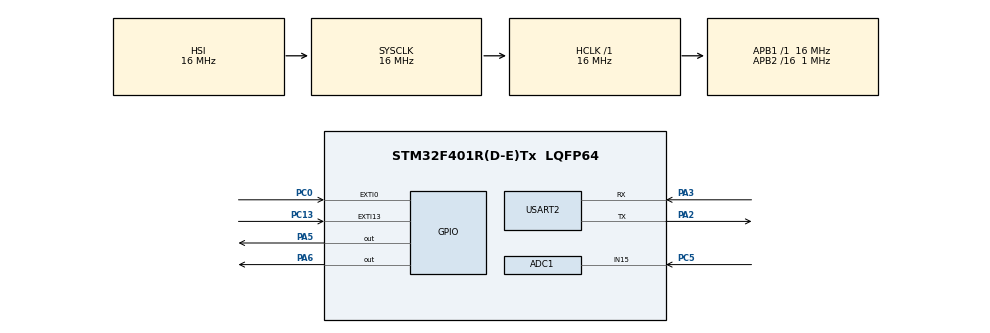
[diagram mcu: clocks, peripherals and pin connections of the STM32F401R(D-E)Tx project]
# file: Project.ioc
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ADC1.Channel-4\#ChannelRegularConversion=ADC_CHANNEL_15
ADC1.NbrOfConversionFlag=1
ADC1.Rank-4\#ChannelRegularConversion=1
ADC1.SamplingTime-4\#ChannelRegularConversion=ADC_SAMPLETIME_3CYCLES
ADC1.master=1
Dma.Request0=USART2_RX
Dma.Request1=USART2_TX
Dma.USART2_RX.0.Direction=DMA_PERIPH_TO_MEMORY
Dma.USART2_RX.0.FIFOMode=DMA_FIFOMODE_DISABLE
Dma.USART2_RX.0.Instance=DMA1_Stream5
Dma.USART2_RX.0.MemDataAlignment=DMA_MDATAALIGN_BYTE
Dma.USART2_RX.0.MemInc=DMA_MINC_ENABLE
Dma.USART2_RX.0.Mode=DMA_NORMAL
Dma.USART2_RX.0.PeriphDataAlignment=DMA_PDATAALIGN_BYTE
Dma.USART2_RX.0.PeriphInc=DMA_PINC_DISABLE
Dma.USART2_RX.0.Priority=DMA_PRIORITY_LOW
Dma.USART2_TX.1.Direction=DMA_MEMORY_TO_PERIPH
Dma.USART2_TX.1.FIFOMode=DMA_FIFOMODE_DISABLE
Dma.USART2_TX.1.Instance=DMA1_Stream6
Dma.USART2_TX.1.MemDataAlignment=DMA_MDATAALIGN_BYTE
Dma.USART2_TX.1.MemInc=DMA_MINC_ENABLE
Dma.USART2_TX.1.Mode=DMA_NORMAL
Dma.USART2_TX.1.PeriphDataAlignment=DMA_PDATAALIGN_BYTE
Dma.USART2_TX.1.PeriphInc=DMA_PINC_DISABLE
Dma.USART2_TX.1.Priority=DMA_PRIORITY_LOW
MBEDTLS.MBEDTLS_CIPHER_MODE_CBC=1
MBEDTLS.MBEDTLS_PKCS5_C=1
Mcu.Family=STM32F4
Mcu.Name=STM32F401R(D-E)Tx
Mcu.Package=LQFP64
NVIC.DMA1_Stream5_IRQn=true\:0\:0\:false\:false\:true\:false\:true\:true
NVIC.DMA1_Stream6_IRQn=true\:0\:0\:false\:false\:true\:false\:true\:true
NVIC.EXTI0_IRQn=true\:0\:0\:false\:false\:true\:true\:true\:true
NVIC.EXTI15_10_IRQn=true\:0\:0\:false\:false\:true\:true\:true\:true
NVIC.PriorityGroup=NVIC_PRIORITYGROUP_4
NVIC.TIM1_UP_TIM10_IRQn=true\:0\:0\:false\:false\:true\:true\:true\:true
NVIC.USART2_IRQn=true\:0\:0\:false\:false\:true\:true\:true\:true
PA2.Mode=Asynchronous
PA2.Signal=USART2_TX
PA3.Mode=Asynchronous
PA3.Signal=USART2_RX
PA5.Signal=GPIO_Output
PA6.Signal=GPIO_Output
PC0.GPIO_ModeDefaultEXTI=GPIO_MODE_IT_FALLING
PC0.GPIO_PuPd=GPIO_PULLUP
PC0.Signal=GPXTI0
PC13-ANTI_TAMP.Signal=GPXTI13
PC5.Signal=ADCx_IN15
ProjectManager.HeapSize=0x200
ProjectManager.StackSize=0x400
ProjectManager.TargetToolchain=Makefile
RCC.AHBFreq_Value=16000000
RCC.APB1Freq_Value=16000000
RCC.APB1TimFreq_Value=16000000
RCC.APB2CLKDivider=RCC_HCLK_DIV16
RCC.APB2Freq_Value=1000000
RCC.APB2TimFreq_Value=2000000
RCC.CortexFreq_Value=16000000
RCC.HCLKFreq_Value=16000000
RCC.HSE_VALUE=25000000
RCC.HSI_VALUE=16000000
RCC.LSE_VALUE=32768
RCC.SYSCLKFreq_VALUE=16000000
RCC.VCOOutputFreq_Value=192000000
SH.ADCx_IN15.0=ADC1_IN15,IN15
TIM10.Period=250 - 1
TIM10.Prescaler=2000 - 1
USART2.VirtualMode=VM_ASYNC
VP_MBEDTLS_VS_MBEDTLS.Mode=Enabled
VP_TIM10_VS_ClockSourceINT.Mode=Enable_Timer
board=custom

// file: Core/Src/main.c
/* USER CODE BEGIN Header */
/**
  ******************************************************************************
  * @file           : main.c
  * @brief          : Main program body
  ******************************************************************************
  * @attention
  *
  * Copyright (c) 2023 STMicroelectronics.
  * All rights reserved.
  *
  * This software is licensed under terms that can be found in the LICENSE file
  * in the root directory of this software component.
  * If no LICENSE file comes with this software, it is provided AS-IS.
  *
  ******************************************************************************
  */
/* USER CODE END Header */
#include "main.h"
#include "mbedtls.h"

/* USER CODE BEGIN Includes */
#include <stdio.h>
#include "logic.h"
#include "stm32f4xx_hal.h"

/* USER CODE END Includes */

ADC_HandleTypeDef hadc1;

TIM_HandleTypeDef htim10;

UART_HandleTypeDef huart2;
DMA_HandleTypeDef hdma_usart2_rx;
DMA_HandleTypeDef hdma_usart2_tx;

/* USER CODE BEGIN PV */

Key key = {
    .generated = 0,
    .value = { 0 },
};

/* USER CODE END PV */

void SystemClock_Config(void);
static void MX_GPIO_Init(void);
static void MX_DMA_Init(void);
static void MX_TIM10_Init(void);
static void MX_USART2_UART_Init(void);
static void MX_ADC1_Init(void);

int main(void)
{

  /* MCU Configuration--------------------------------------------------------*/

  /* Reset of all peripherals, Initializes the Flash interface and the Systick. */
  HAL_Init();

  /* Configure the system clock */
  SystemClock_Config();

  /* Initialize all configured peripherals */
  MX_GPIO_Init();
  MX_DMA_Init();
  MX_TIM10_Init();
  MX_USART2_UART_Init();
  MX_MBEDTLS_Init();
  MX_ADC1_Init();
  /* USER CODE BEGIN 2 */
  HAL_TIM_Base_Start_IT(&htim10);

  /* USER CODE END 2 */

  /* Infinite loop */
  /* USER CODE BEGIN WHILE */
  HAL_UART_Receive_IT(&huart2, (uint8_t *)&header, 2);
  // printf("hello it's %lu at %x\r\n", key, (uint32_t)&key);
  while (1)
  {
    /* USER CODE END WHILE */

  }
}

void SystemClock_Config(void)
{
  RCC_OscInitTypeDef RCC_OscInitStruct = {0};
  RCC_ClkInitTypeDef RCC_ClkInitStruct = {0};

  /** Configure the main internal regulator output voltage
  */
  __HAL_RCC_PWR_CLK_ENABLE();
  __HAL_PWR_VOLTAGESCALING_CONFIG(PWR_REGULATOR_VOLTAGE_SCALE2);

  /** Initializes the RCC Oscillators according to the specified parameters
  * in the RCC_OscInitTypeDef structure.
  */
  RCC_OscInitStruct.OscillatorType = RCC_OSCILLATORTYPE_HSI;
  RCC_OscInitStruct.HSIState = RCC_HSI_ON;
  RCC_OscInitStruct.HSICalibrationValue = RCC_HSICALIBRATION_DEFAULT;
  RCC_OscInitStruct.PLL.PLLState = RCC_PLL_NONE;
  if (HAL_RCC_OscConfig(&RCC_OscInitStruct) != HAL_OK)
  {
    Error_Handler();
  }

  /** Initializes the CPU, AHB and APB buses clocks
  */
  RCC_ClkInitStruct.ClockType = RCC_CLOCKTYPE_HCLK|RCC_CLOCKTYPE_SYSCLK
                              |RCC_CLOCKTYPE_PCLK1|RCC_CLOCKTYPE_PCLK2;
  RCC_ClkInitStruct.SYSCLKSource = RCC_SYSCLKSOURCE_HSI;
  RCC_ClkInitStruct.AHBCLKDivider = RCC_SYSCLK_DIV1;
  RCC_ClkInitStruct.APB1CLKDivider = RCC_HCLK_DIV1;
  RCC_ClkInitStruct.APB2CLKDivider = RCC_HCLK_DIV16;

  if (HAL_RCC_ClockConfig(&RCC_ClkInitStruct, FLASH_LATENCY_0) != HAL_OK)
  {
    Error_Handler();
  }
}

static void MX_ADC1_Init(void)
{

  ADC_ChannelConfTypeDef sConfig = {0};

   //!!! HAL_ADC_Init is commented because some parameters are missing
  //hadc.Instance = ADC1;
  //hadc.Init.ClockPrescaler = ;
  //hadc.Init.Resolution = ADC_RESOLUTION_12B;
  //hadc.Init.ScanConvMode = DISABLE;
  //hadc.Init.ContinuousConvMode = DISABLE;
  //hadc.Init.DiscontinuousConvMode = DISABLE;
  //hadc.Init.ExternalTrigConvEdge = ADC_EXTERNALTRIGCONVEDGE_NONE;
  //hadc.Init.ExternalTrigConv = ADC_SOFTWARE_START;
  //hadc.Init.DataAlign = ADC_DATAALIGN_RIGHT;
  //hadc.Init.NbrOfConversion = 1;
  //hadc.Init.DMAContinuousRequests = DISABLE;
  //hadc.Init.EOCSelection = ADC_EOC_SINGLE_CONV;
    //HAL_ADC_Init(&hadc);

   //!!! HAL_ADC_ConfigChannel is commented because some parameters are missing
  //sConfig.Channel = ADC_CHANNEL_15;
  //sConfig.Rank = 1;
  //sConfig.SamplingTime = ADC_SAMPLETIME_3CYCLES;
    //HAL_ADC_ConfigChannel(&hadc, &sConfig);

}

static void MX_TIM10_Init(void)
{

  htim10.Instance = TIM10;
  htim10.Init.Prescaler = 2000 - 1;
  htim10.Init.CounterMode = TIM_COUNTERMODE_UP;
  htim10.Init.Period = 250 - 1;
  htim10.Init.ClockDivision = TIM_CLOCKDIVISION_DIV1;
  htim10.Init.AutoReloadPreload = TIM_AUTORELOAD_PRELOAD_DISABLE;
  if (HAL_TIM_Base_Init(&htim10) != HAL_OK)
  {
    Error_Handler();
  }

}

static void MX_USART2_UART_Init(void)
{

  huart2.Instance = USART2;
  huart2.Init.BaudRate = 115200;
  huart2.Init.WordLength = UART_WORDLENGTH_8B;
  huart2.Init.StopBits = UART_STOPBITS_1;
  huart2.Init.Parity = UART_PARITY_NONE;
  huart2.Init.Mode = UART_MODE_TX_RX;
  huart2.Init.HwFlowCtl = UART_HWCONTROL_NONE;
  huart2.Init.OverSampling = UART_OVERSAMPLING_16;
  if (HAL_UART_Init(&huart2) != HAL_OK)
  {
    Error_Handler();
  }

}

static void MX_DMA_Init(void)
{

  /* DMA controller clock enable */
  __HAL_RCC_DMA1_CLK_ENABLE();

  /* DMA interrupt init */
  /* DMA1_Stream5_IRQn interrupt configuration */
  HAL_NVIC_SetPriority(DMA1_Stream5_IRQn, 0, 0);
  HAL_NVIC_EnableIRQ(DMA1_Stream5_IRQn);
  /* DMA1_Stream6_IRQn interrupt configuration */
  HAL_NVIC_SetPriority(DMA1_Stream6_IRQn, 0, 0);
  HAL_NVIC_EnableIRQ(DMA1_Stream6_IRQn);

}

static void MX_GPIO_Init(void)
{
  GPIO_InitTypeDef GPIO_InitStruct = {0};

  /* GPIO Ports Clock Enable */
  __HAL_RCC_GPIOC_CLK_ENABLE();
  __HAL_RCC_GPIOA_CLK_ENABLE();

  /*Configure GPIO pin Output Level */
  HAL_GPIO_WritePin(GPIOA, GPIO_PIN_5|GPIO_PIN_6, GPIO_PIN_RESET);

  /*Configure GPIO pin : PC13 */
  GPIO_InitStruct.Pin = GPIO_PIN_13;
  GPIO_InitStruct.Mode = GPIO_MODE_IT_RISING;
  GPIO_InitStruct.Pull = GPIO_NOPULL;
  HAL_GPIO_Init(GPIOC, &GPIO_InitStruct);

  /*Configure GPIO pin : PC0 */
  GPIO_InitStruct.Pin = GPIO_PIN_0;
  GPIO_InitStruct.Mode = GPIO_MODE_IT_FALLING;
  GPIO_InitStruct.Pull = GPIO_PULLUP;
  HAL_GPIO_Init(GPIOC, &GPIO_InitStruct);

  /*Configure GPIO pins : PA5 PA6 */
  GPIO_InitStruct.Pin = GPIO_PIN_5|GPIO_PIN_6;
  GPIO_InitStruct.Mode = GPIO_MODE_OUTPUT_PP;
  GPIO_InitStruct.Pull = GPIO_NOPULL;
  GPIO_InitStruct.Speed = GPIO_SPEED_FREQ_LOW;
  HAL_GPIO_Init(GPIOA, &GPIO_InitStruct);

  /* EXTI interrupt init*/
  HAL_NVIC_SetPriority(EXTI0_IRQn, 0, 0);
  HAL_NVIC_EnableIRQ(EXTI0_IRQn);

  HAL_NVIC_SetPriority(EXTI15_10_IRQn, 0, 0);
  HAL_NVIC_EnableIRQ(EXTI15_10_IRQn);

}

/* USER CODE BEGIN 4 */

ssize_t _write(int fd, const void *buf, size_t count) {
    if (fd != 1)
        return -1;
    HAL_UART_Transmit(&huart2, buf, count, 1000);
    return count;
}

/* USER CODE END 4 */

void Error_Handler(void)
{
  __disable_irq();
  while (1)
  {
  }
}
